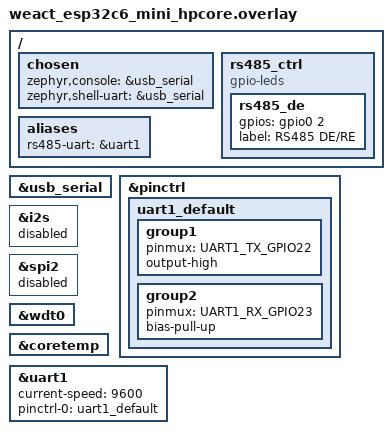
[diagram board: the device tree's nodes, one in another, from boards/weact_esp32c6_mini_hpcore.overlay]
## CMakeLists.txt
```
cmake_minimum_required(VERSION 3.20.0)
find_package(Zephyr REQUIRED HINTS $ENV{ZEPHYR_BASE})

project(ami-lwm2m-client
    VERSION 0.6.43
    DESCRIPTION "AMI Node: LwM2M client over Thread (ESP32-C6)"
    LANGUAGES C
)

# Source files
target_sources(app PRIVATE
    src/main.c
    src/lwm2m_discover.c
    src/lwm2m_watchdog.c
    src/hw_watchdog.c
    src/rgb_led.c
    src/lwm2m_obj_power_meter.c
    src/firmware_update.c
    src/thread_conn_monitor.c
    src/lwm2m_obj_thread_net.c
    src/lwm2m_obj_thread_neighbor.c
    src/lwm2m_obj_thread_commission.c
    src/lwm2m_obj_thread_cli.c
    src/rs485_uart.c
    src/dlms_hdlc.c
    src/dlms_cosem.c
    src/dlms_meter.c
    src/post_mortem.c
    src/lwm2m_obj_light_control.c
    src/lwm2m_obj_thread_role.c
    src/coap_keepalive.c
    src/coap_diag.c
)

# Include path for custom LwM2M object internal headers
target_include_directories(app PRIVATE
    ${ZEPHYR_BASE}/subsys/net/lib/lwm2m
)

# CoAP diag server (src/coap_diag.c): COAP_SERVICE_DEFINE(diag_service, ...)
# places its resources into a per-service iterable section
# "coap_resource_diag_service". Register that section on BOTH linker paths so
# the _coap_resource_diag_service_list_start/end symbols resolve. See
# sections-ram.ld and samples/net/sockets/coap_server for the upstream pattern.
zephyr_linker_sources(DATA_SECTIONS sections-ram.ld)
zephyr_iterable_section(
    NAME coap_resource_diag_service
    GROUP DATA_REGION ${XIP_ALIGN_WITH_INPUT})
```

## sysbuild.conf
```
# Sysbuild configuration — only consumed when building with `west build --sysbuild`.
#
# v0.6.27 OTA: enable the MCUboot bootloader image. sysbuild builds two
# images: the MCUboot 2nd-stage bootloader (flashed at 0x0 / boot_partition)
# and this app, signed + headered, linked to run from slot0_partition
# (0x20000). MCUboot validates the signature/header at boot and chain-loads
# slot0, or swaps in a pending image from slot1 after an OTA.
#
# The legacy non-sysbuild build (tools/build_firmware.py) is unaffected: it
# never passes --sysbuild, so this file is ignored and the monolithic
# image-at-0x0 build still works for nodes not yet migrated to MCUboot.
SB_CONFIG_BOOTLOADER_MCUBOOT=y
```

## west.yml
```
# West manifest for the AMI LwM2M Node firmware (freestanding Zephyr application).
#
# This pins the EXACT Zephyr revision the firmware was built + validated on:
#   Zephyr 4.3.99 dev snapshot  (v4.3.0-6612-g6159cb3fecf)
#   Zephyr SDK 0.17.0 · west 1.5.0 · esptool 5.2.0 · board xiao_esp32c6/esp32c6/hpcore
#
# Reproduce the workspace on a fresh machine:
#   mkdir ami-ws && cd ami-ws
#   git clone https://github.com/jsebgiraldo/ami-lwm2m-node.git
#   west init -l ami-lwm2m-node
#   west update            # pulls Zephyr + modules at the pinned revision (large)
#   west zephyr-export
#   pip install -r ami-lwm2m-node/requirements.txt
#   pip install -r zephyr/scripts/requirements.txt
# Then apply the out-of-tree hook (tools/ZEPHYR_PATCHES.md) and build
# (python ami-lwm2m-node/tools/build_prod.py). See README.md.
manifest:
  version: "1.0"
  remotes:
    - name: zephyrproject-rtos
      url-base: https://github.com/zephyrproject-rtos
  projects:
    - name: zephyr
      remote: zephyrproject-rtos
      revision: 6159cb3fecf85090c8d552d5dfa4d97f4cb1231e
      # import: true pulls Zephyr's full module set at this revision — heavier
      # but guarantees a complete, build-able tree (no missing-module surprises).
      # To trim for ESP32-C6 only, replace with an import: { name-allowlist: [...] }.
      import: true
  self:
    path: ami-lwm2m-node
```

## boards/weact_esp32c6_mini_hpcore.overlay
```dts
/*
 * Devicetree overlay for WeAct ESP32-C6 Mini / ESP32-C6 SuperMini
 * (drop-in replacement for the Seeed XIAO ESP32-C6 in this fleet)
 *
 * Differences vs xiao_esp32c6_hpcore.overlay:
 *   - Console stays on the board-default UART0 (GPIO16/17), NOT usb_serial
 *     — that's how the WeAct board.dts wires its USB-C through.
 *   - SPI2 default pinmux on the WeAct DTS uses GPIO2 for SCLK, which
 *     collides with our RS485 DE/RE on GPIO2. We disable spi2 to keep
 *     GPIO2 free.
 *   - Single onboard LED on GPIO8 (WeAct uses it as WS2812 RGB via I2S
 *     in its DTS; we disable that and drive it via the existing
 *     direct-register WS2812 bit-bang in src/rgb_led.c which already
 *     targets GPIO8 — see header note in that file).
 *
 * DLMS RS485 wiring (same as XIAO):
 *   UART1 TX = GPIO22  (D4 equivalent on XIAO)
 *   UART1 RX = GPIO23
 *   DE/RE    = GPIO2   (HIGH = TX)
 */

#include <zephyr/dt-bindings/pinctrl/esp-pinctrl-common.h>
#include <zephyr/dt-bindings/pinctrl/esp32c6-pinctrl.h>
#include <zephyr/dt-bindings/pinctrl/esp32c6-gpio-sigmap.h>

/* The WeAct board DTS routes the console to UART0 (GPIO16/17) — that
 * matches their boards which solder a CH340/CP2102 between USB-C and
 * UART0. The ESP32-C6 SuperMini wires USB-C straight to the chip's
 * native USB-Serial-JTAG (GPIO12/13), so we override the chosen console
 * to usb_serial; that way `west monitor` / pyserial on the COM port the
 * board enumerates as actually sees the firmware logs.
 */
/ {
	chosen {
		zephyr,console = &usb_serial;
		zephyr,shell-uart = &usb_serial;
	};
};

&usb_serial {
	status = "okay";
};

&pinctrl {
	uart1_default: uart1_default {
		group1 {
			pinmux = <UART1_TX_GPIO22>;
			output-high;
		};
		group2 {
			pinmux = <UART1_RX_GPIO23>;
			bias-pull-up;
		};
	};
};

/* Disable WeAct's I2S-driven WS2812 — we drive GPIO8 directly from
 * src/rgb_led.c (bit-bang, same as on XIAO). */
&i2s {
	status = "disabled";
};

/* Disable SPI2 — its default SCLK pin collides with our RS485 DE/RE (GPIO2). */
&spi2 {
	status = "disabled";
};

/* WeAct's I2C0 lives on GPIO14/15 which don't collide with anything we
 * need — leave it on for now (the application doesn't use it). */

/* HW watchdog backstop (same role as on XIAO). */
&wdt0 {
	status = "okay";
};

/* On-die temperature sensor. */
&coretemp {
	status = "okay";
};

/* DLMS RS485 UART. */
&uart1 {
	status = "okay";
	current-speed = <9600>;
	pinctrl-0 = <&uart1_default>;
	pinctrl-names = "default";
};

/* RS485 DE/RE control as a plain GPIO + a led0 alias the rgb_led driver
 * doesn't need but other code (and Zephyr conventions) expect. */
/ {
	rs485_ctrl: rs485_ctrl {
		compatible = "gpio-leds";  /* reuse for a single GPIO node */
		rs485_de: rs485_de {
			gpios = <&gpio0 2 GPIO_ACTIVE_HIGH>;
			label = "RS485 DE/RE";
		};
	};

	aliases {
		rs485-uart = &uart1;
	};
};
```

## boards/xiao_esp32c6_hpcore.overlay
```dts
/*
 * Devicetree overlay for XIAO ESP32-C6 + Seeed RS485 Expansion Board
 *
 * Seeed RS485 Expansion Board wiring (per Seeed wiki & TP8485E transceiver):
 *   D4 (GPIO22) = TX  (MCU → transceiver DI → RS485 bus)
 *   D5 (GPIO23) = RX  (RS485 bus → transceiver RO → MCU)
 *   D2 (GPIO2)  = DE/RE  (HIGH = transmit, LOW = receive)
 *
 * We configure UART1 on GPIO22(TX)/GPIO23(RX) for DLMS/COSEM serial
 * communication with the Microstar smart meter.
 *
 * Note: GPIO22/GPIO23 are shared with I2C0 — I2C is disabled here.
 */

#include <zephyr/dt-bindings/pinctrl/esp-pinctrl-common.h>
#include <zephyr/dt-bindings/pinctrl/esp32c6-pinctrl.h>
#include <zephyr/dt-bindings/pinctrl/esp32c6-gpio-sigmap.h>
#include <zephyr/dt-bindings/led/led.h>

/* Add UART1 pin configuration */
&pinctrl {
	uart1_default: uart1_default {
		group1 {
			pinmux = <UART1_TX_GPIO22>;
			output-high;
		};

		group2 {
			pinmux = <UART1_RX_GPIO23>;
			bias-pull-up;
		};
	};

	/* v0.6.54: SPI2 binding REVERTED -- enabling SPI was breaking the
	 * 802.15.4 radio attach. WS2812 reverts to custom bit-bang in rgb_led.c. */
};

/* Disable I2C0 since GPIO22/23 are now used for UART1 (RS485) */
&i2c0 {
	status = "disabled";
};

/* Enable Timer-Group 0 hardware watchdog (v0.6.13+, PRIO 9).
 * Last-resort defense against firmware hangs that the soft watchdog
 * cannot recover from (system_workq stuck, scheduler stalled, USB
 * drain blocked at sys_reboot). Driven via Zephyr's task_wdt subsystem
 * — see src/hw_watchdog.c. */
&wdt0 {
	status = "okay";
};

/* Enable on-die temperature sensor (v0.6.11+).
 * Used to monitor SoC self-heating during operation. Read via
 * sensor_sample_fetch + sensor_channel_get(SENSOR_CHAN_DIE_TEMP).
 * Range: -40°C to +125°C. Accuracy ~±2°C after factory calibration. */
&coretemp {
	status = "okay";
};

/* v0.6.34 dropped CPU to 80 MHz to cut self-heating; v0.6.36 REVERTED to
 * 160 MHz (no override here — falls back to the SoC default in
 * esp32c6_common.dtsi). Reason: 80 MHz roughly halves blockwise CoAP/MCUboot
 * throughput, pushing single-node OTA from ~10 min (160) to >50 min (80) —
 * past the Edge's LWM2M_TIMEOUT=600000 (10 min), so transfers loop in state=1
 * Downloading and never reach Downloaded. Measured A/B: d2b4 @ 160MHz reached
 * Downloaded in 10.3 min; c61c @ 80MHz never finished in 50+ min over two
 * attempts. The thermal gain was only ~2C avg (radio rx-on dominates heat),
 * not worth losing fleet OTA. Keeping DLMS_POLL=60s + NOTIFY=60s for the mesh
 * load reduction (those don't affect CPU throughput). */

/* Enable UART1 for RS485 DLMS communication */
&uart1 {
	status = "okay";
	current-speed = <9600>;
	pinctrl-0 = <&uart1_default>;
	pinctrl-names = "default";
};

/* RS485 DE/RE control pin — defined as a GPIO node */
/ {
	rs485_ctrl: rs485_ctrl {
		compatible = "gpio-leds";  /* Reuse gpio-leds compatible for simple GPIO */
		rs485_de: rs485_de {
			gpios = <&gpio0 2 GPIO_ACTIVE_HIGH>;
			label = "RS485 DE/RE";
		};
	};

	aliases {
		rs485-uart = &uart1;
	};

};

/* v0.6.54: WS2812 SPI binding REVERTED -- v0.6.53 enabling CONFIG_SPI=y broke
 * the 802.15.4 radio attach across all 30 nodes (1h soak collapsed mesh from
 * 15 active to 0). LED driver returns to custom bit-bang in src/rgb_led.c. */
```

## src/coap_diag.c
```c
/*
 * Object 33001 gives the server LwM2M-mediated role control; this gives the
 * server a *direct* IPv6 read path. A minimal CoAP GET server on port 5685
 * exposing two resources, both independent of the LwM2M registration:
 *
 *   coap://[<node-ipv6>]:5685/diag  -> node status snapshot (JSON)
 *      {"fw":"0.7.15-diag","role":"Router","uptime_s":1234,"resets":7,
 *       "reg_ok":3,"recover":5,"wdog":0,"boot_burst":0,
 *       "partition":123456,"rloc16":"0x4c00"}
 *
 *   coap://[<node-ipv6>]:5685/ami   -> live AMI metering / active OBIS (JSON)
 *      {"valid":true,"vr":122.24,...,"ptot":0.03,"eact":61100.0,"freq":59.94,
 *       "reads":15,"errs":0,"mask":"0x0007ffff","age_s":3}
 *
 * Useful precisely for the "inactive on TB" nodes: if a node is still on the
 * Thread mesh it answers these GETs even when its LwM2M session is down, so the
 * server can tell "reachable but not registered" from "off the mesh" AND pull
 * the instantaneous meter reading without waiting on the LwM2M Observe cadence.
 */
#include <zephyr/kernel.h>
#include <zephyr/logging/log.h>
#include <zephyr/net/socket.h>
#include <zephyr/net/coap.h>
#include <zephyr/net/coap_service.h>
#include <zephyr/net/openthread.h>
#include <openthread/instance.h>
#include <openthread/thread.h>
#include <stdio.h>
#include <string.h>

#include "coap_diag.h"
#include "dlms_meter.h"

LOG_MODULE_REGISTER(coap_diag, LOG_LEVEL_INF);

/* Diagnostic counter getters (defined in main.c). */
extern uint32_t lwm2m_diag_get_total_resets(void);
extern uint32_t lwm2m_diag_get_reg_success(void);
extern uint32_t lwm2m_diag_get_recover_count(void);
extern uint32_t lwm2m_diag_get_watchdog_count(void);
extern uint32_t lwm2m_diag_get_boot_burst(void);

/* Current meter readings snapshot (main.c). Reads last_readings, which is
 * populated in BOTH demo and real modes — see ami_get_last_readings(). */
extern bool ami_get_last_readings(struct meter_readings *out);

static const char *g_fw = "?";

/* CoAP diag server: distinct port so it never collides with the LwM2M client's
 * sockets. Auto-starts once the network interface is up. */
static uint16_t coap_diag_port = 5685;
COAP_SERVICE_DEFINE(diag_service, "::", &coap_diag_port, COAP_SERVICE_AUTOSTART);

/* Payload budget: leave headroom under the server message size for the CoAP
 * header + token + Content-Format option (~16 bytes) so append_payload never
 * overflows the response buffer. */
#define DIAG_JSON_MAX  (CONFIG_COAP_SERVER_MESSAGE_SIZE - 64)

static const char *role_str(otDeviceRole r)
{
	switch (r) {
	case OT_DEVICE_ROLE_DISABLED: return "Disabled";
	case OT_DEVICE_ROLE_DETACHED: return "Detached";
	case OT_DEVICE_ROLE_CHILD:    return "Child";
	case OT_DEVICE_ROLE_ROUTER:   return "Router";
	case OT_DEVICE_ROLE_LEADER:   return "Leader";
	default:                      return "?";
	}
}

/* Build + send a 2.05 Content response carrying `json` (len bytes) as
 * application/json, echoing the request token/mid and ACK-ing CON requests. */
static int diag_send_json(struct coap_resource *resource, struct coap_packet *request,
			  struct sockaddr *addr, socklen_t addr_len,
			  const char *json, int len)
{
	uint8_t data[CONFIG_COAP_SERVER_MESSAGE_SIZE];
	struct coap_packet response;
	uint8_t token[COAP_TOKEN_MAX_LEN];
	uint16_t id = coap_header_get_id(request);
	uint8_t tkl = coap_header_get_token(request, token);
	uint8_t type = (coap_header_get_type(request) == COAP_TYPE_CON)
		       ? COAP_TYPE_ACK : COAP_TYPE_NON_CON;

	int r = coap_packet_init(&response, data, sizeof(data), COAP_VERSION_1, type,
				 tkl, token, COAP_RESPONSE_CODE_CONTENT, id);
	if (r < 0) {
		return r;
	}
	r = coap_append_option_int(&response, COAP_OPTION_CONTENT_FORMAT,
				   COAP_CONTENT_FORMAT_APP_JSON);
	if (r < 0) {
		return r;
	}
	r = coap_packet_append_payload_marker(&response);
	if (r < 0) {
		return r;
	}
	r = coap_packet_append_payload(&response, json, len);
	if (r < 0) {
		return r;
	}
	return coap_resource_send(resource, &response, addr, addr_len, NULL);
}

static int diag_get(struct coap_resource *resource, struct coap_packet *request,
		    struct sockaddr *addr, socklen_t addr_len)
{
	otInstance *ot = openthread_get_default_instance();
	otDeviceRole role = ot ? otThreadGetDeviceRole(ot) : OT_DEVICE_ROLE_DISABLED;
	uint32_t partition = ot ? otThreadGetPartitionId(ot) : 0;
	uint16_t rloc16 = ot ? otThreadGetRloc16(ot) : 0;
	uint32_t up = (uint32_t)(k_uptime_get() / 1000);

	char json[DIAG_JSON_MAX];
	int len = snprintf(json, sizeof(json),
		"{\"fw\":\"%s\",\"role\":\"%s\",\"uptime_s\":%u,\"resets\":%u,"
		"\"reg_ok\":%u,\"recover\":%u,\"wdog\":%u,\"boot_burst\":%u,"
		"\"partition\":%u,\"rloc16\":\"0x%04x\"}",
		g_fw, role_str(role), up,
		lwm2m_diag_get_total_resets(), lwm2m_diag_get_reg_success(),
		lwm2m_diag_get_recover_count(), lwm2m_diag_get_watchdog_count(),
		lwm2m_diag_get_boot_burst(), partition, rloc16);
	if (len < 0 || len >= (int)sizeof(json)) {
		len = (int)sizeof(json) - 1;
	}
	return diag_send_json(resource, request, addr, addr_len, json, len);
}

static int ami_get(struct coap_resource *resource, struct coap_packet *request,
		   struct sockaddr *addr, socklen_t addr_len)
{
	struct meter_readings m;
	bool have = ami_get_last_readings(&m);

	char json[DIAG_JSON_MAX];
	int len;
	if (!have) {
		/* No successful DLMS read yet (no meter attached, or bus down). */
		len = snprintf(json, sizeof(json), "{\"valid\":false}");
	} else {
		int64_t age_s = (k_uptime_get() - m.timestamp_ms) / 1000;
		len = snprintf(json, sizeof(json),
			"{\"valid\":true,"
			"\"vr\":%.2f,\"vs\":%.2f,\"vt\":%.2f,"
			"\"ir\":%.3f,\"is\":%.3f,\"it\":%.3f,"
			"\"pr\":%.3f,\"ps\":%.3f,\"pt\":%.3f,"
			"\"ptot\":%.3f,\"qtot\":%.3f,\"stot\":%.3f,\"pf\":%.3f,"
			"\"eact\":%.3f,\"ereact\":%.3f,\"eapp\":%.3f,"
			"\"freq\":%.2f,"
			"\"reads\":%d,\"errs\":%d,\"mask\":\"0x%08x\",\"age_s\":%lld}",
			m.voltage_r, m.voltage_s, m.voltage_t,
			m.current_r, m.current_s, m.current_t,
			m.active_power_r, m.active_power_s, m.active_power_t,
			m.total_active_power, m.total_reactive_power,
			m.total_apparent_power, m.total_power_factor,
			m.active_energy, m.reactive_energy, m.apparent_energy,
			m.frequency,
			m.read_count, m.error_count, m.field_mask,
			(long long)age_s);
	}
	if (len < 0 || len >= (int)sizeof(json)) {
		len = (int)sizeof(json) - 1;
	}
	return diag_send_json(resource, request, addr, addr_len, json, len);
}

static const char * const diag_path[] = { "diag", NULL };
COAP_RESOURCE_DEFINE(diag_resource, diag_service, {
	.get = diag_get,
	.path = diag_path,
});

static const char * const ami_path[] = { "ami", NULL };
COAP_RESOURCE_DEFINE(ami_resource, diag_service, {
	.get = ami_get,
	.path = ami_path,
});

int coap_diag_init(const char *fw_version)
{
	if (fw_version) {
		g_fw = fw_version;
	}
	LOG_INF("CoAP diag GET server up on [::]:%u  /diag (node) + /ami (meter)",
		coap_diag_port);
	return 0;
}
```

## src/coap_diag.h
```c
#ifndef COAP_DIAG_H
#define COAP_DIAG_H

/* Object-independent, on-demand IPv6 diagnostics.
 *
 * Starts a tiny CoAP server (Zephyr coap_service) that answers a GET to
 *   coap://[<node-ipv6>]:5685/diag
 * with a JSON snapshot of the node's live state (role, uptime, resets,
 * registration counters, partition, rloc16). Works over the node's Thread
 * IPv6 address and is INDEPENDENT of LwM2M/CoAP-observe — so the server can
 * query a node directly even when it is not registered on TB.
 *
 * Call once after OpenThread is initialised; the service auto-starts when the
 * network comes up. Pass the firmware version string so it is reported.
 */
int coap_diag_init(const char *fw_version);

#endif /* COAP_DIAG_H */
```

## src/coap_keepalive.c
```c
/*
 * CoAP-level keepalive — see header for design notes.
 *
 * Why notify on TD_UPTIME_S_RID rather than introduce a new resource:
 *   - It's already declared observable on TB Edge (we depend on this
 *     for liveness in tools/tb_edge_monitoring_setup.py OBSERVE_ADDITIONS).
 *   - conn_monitor already updates it every ~60s, so the value is
 *     non-stale; we just bump the notify cadence floor to 300s without
 *     duplicating state.
 *   - Engine pmin/pmax write-attributes on /33000/0/10 (typical pmin=30,
 *     pmax=300 from TB Edge) won't suppress us — we fire exactly at pmax.
 *
 * Boot grace: wait 60s before the first keepalive so the LwM2M engine
 * has time to complete REGISTER. If we fire before REGISTER ACK, the
 * notify is silently dropped (no observer to notify against), which is
 * fine but pollutes early-boot logs.
 */

#include "coap_keepalive.h"

#include <zephyr/kernel.h>
#include <zephyr/logging/log.h>
#include <zephyr/net/lwm2m.h>
#include <zephyr/sys/atomic.h>

#include "lwm2m_obj_thread_diag.h"
#include "lwm2m_watchdog.h"
#include "hw_watchdog.h"

LOG_MODULE_REGISTER(coap_keepalive, LOG_LEVEL_INF);

#define KEEPALIVE_PERIOD_S    CONFIG_AMI_COAP_KEEPALIVE_PERIOD_S
#define KEEPALIVE_BOOT_GRACE_S 60
/* v0.6.69: was 1024 — code-review audit caught the same pattern that
 * bit lwm2m_wdog in v0.6.63: LOG_WRN/LOG_ERR with %s/%u args triggers
 * cbprintf_package_convert recursion needing ~3 KB headroom. First fail
 * burst (~270 s after socket dies) overflowed the 1024-byte stack and
 * silently killed the keepalive thread → board sat as zombie because
 * no further notifies attempted → silence watchdog never saw heartbeat
 * absence. This was a candidate root cause of the 8/30 stuck boards in
 * v0.6.67's 2h soak. 4096 mirrors lwm2m_wdog headroom. */
#define KEEPALIVE_STACK_SZ    4096
/* Preemptive prio — not coop — so it cannot starve LwM2M engine threads.
 * Priority chosen well below lwm2m_wdog (PREEMPT 7) so the silence
 * watchdog still has precedence if it ever decides to act. */
#define KEEPALIVE_PRIO        K_PRIO_PREEMPT(9)

/* v0.6.68: when notify_observer() fails N times in a row, the engine is
 * almost certainly in a stuck state (ECANCELED, socket dead, etc.). Fire
 * recover_work directly instead of waiting for the silence watchdog.
 * N=3 chosen to match the engine's internal CoAP CON retransmit budget. */
#define KEEPALIVE_FAIL_THRESHOLD 3

/* Diag — increment on every keepalive emit so the operator can verify
 * via Object 33000 that the worker is actually running. */
static atomic_t keepalive_emit_count = ATOMIC_INIT(0);
/* v0.6.68: consecutive failed notify_observer() returns. Reset on success. */
static atomic_t keepalive_consec_fail = ATOMIC_INIT(0);

/* Hook into main.c's recover_work — same path the silence watchdog uses. */
extern struct k_work_delayable lwm2m_recover_work;
extern void lwm2m_diag_record_error(int err);

uint32_t coap_keepalive_get_emit_count(void)
{
	return (uint32_t)atomic_get(&keepalive_emit_count);
}

uint32_t coap_keepalive_get_consec_fail(void)
{
	return (uint32_t)atomic_get(&keepalive_consec_fail);
}

static void keepalive_thread_fn(void *p1, void *p2, void *p3)
{
	ARG_UNUSED(p1); ARG_UNUSED(p2); ARG_UNUSED(p3);

	LOG_INF("CoAP keepalive thread up: period=%us, grace=%us, "
		"target=/33000/0/%u (uptime_s)",
		KEEPALIVE_PERIOD_S, KEEPALIVE_BOOT_GRACE_S,
		TD_UPTIME_S_RID);

	/* Don't fight the boot REGISTER. */
	k_sleep(K_SECONDS(KEEPALIVE_BOOT_GRACE_S));

	for (;;) {
		/* Notify the engine that /33000/0/uptime_s "changed" — engine
		 * will queue a CoAP CON message. If the socket is dead the
		 * engine's notify_message_timeout_cb() fires after 3 retries
		 * and calls lwm2m_rd_client_timeout(), which kicks the state
		 * machine back to ENGINE_DO_REGISTRATION. Our recover_work in
		 * main.c rides the same state machine.
		 */
		int ret = lwm2m_notify_observer(THREAD_DIAG_OBJECT_ID, 0,
						TD_UPTIME_S_RID);
		atomic_inc(&keepalive_emit_count);

		if (ret >= 0) {
			/* v0.6.75: ret is the COUNT of observers notified, NOT a
			 * 0=OK status. lwm2m_notify_observer_path() returns the
			 * number of matching observers (0 = none) or <0 on a real
			 * engine error. The v0.6.68 code tested `ret == 0` as
			 * "queued OK", which INVERTED the logic: a board that IS
			 * being observed on /33000/0/uptime_s returns ret>0 and was
			 * mis-counted as a failure → 3 strikes → forced recover →
			 * COLD reboot every ~12 min (3 × keepalive_period after the
			 * 60 s boot grace). Boards with NO observer (ret==0, e.g.
			 * minimal builds without Object 33000) were the only ones
			 * that survived — the perverse opposite of what we want.
			 * Forensic proof: 1494 (Object 33000 + observed) looped at
			 * uptime≈706 s / reg_age≈660 s with heap 100 % free; f7b4/
			 * fbb8 (minimal, ret==0) stayed up. ret>=0 means the engine
			 * processed the notify (alive) — feed the watchdog. */
			lwm2m_watchdog_emit_event();
			atomic_set(&keepalive_consec_fail, 0);
			/* v0.7.9: ret>0 = REAL observers were notified, so telemetry
			 * is actually being delivered (not just queued). Feed the
			 * inbound delivery-liveness gate. ret==0 = registered but
			 * NOBODY is observing us — the stuck-session signature — so we
			 * deliberately do NOT feed it: after
			 * CONFIG_AMI_DELIVERY_LIVENESS_TIMEOUT_S the HW feeder cold-
			 * resets, forcing a fresh REGISTER that re-establishes observes.
			 * The note_delivery() latch (ever_had_observer) means a build
			 * that is never observed never arms this gate. */
			if (ret > 0) {
				hw_watchdog_note_delivery();
			}
			LOG_DBG("keepalive: notify ok, %d observer(s) (cnt=%u)",
				ret, (uint32_t)atomic_get(&keepalive_emit_count));
		} else {
			/* v0.6.68: real engine error (ret < 0, e.g. -ENOMEM /
			 * socket dead). Count consecutive fails; after
			 * KEEPALIVE_FAIL_THRESHOLD, kick recover directly. This
			 * catches stuck states the silence watchdog cannot see fast
			 * enough (engine internally cancelled / socket dead). */
			int fails = (int)atomic_inc(&keepalive_consec_fail) + 1;
			LOG_WRN("keepalive: notify failed ret=%d "
				"(consec=%d/%d, cnt=%u)",
				ret, fails, KEEPALIVE_FAIL_THRESHOLD,
				(uint32_t)atomic_get(&keepalive_emit_count));
			if (fails >= KEEPALIVE_FAIL_THRESHOLD) {
				LOG_ERR("keepalive: %d consecutive failures — "
					"forcing recover_work", fails);
				lwm2m_diag_record_error(ret);
				atomic_set(&keepalive_consec_fail, 0);
				k_work_reschedule(&lwm2m_recover_work,
						  K_NO_WAIT);
			}
		}

		k_sleep(K_SECONDS(KEEPALIVE_PERIOD_S));
	}
}

K_THREAD_STACK_DEFINE(keepalive_stack, KEEPALIVE_STACK_SZ);
static struct k_thread keepalive_thread_data;

void coap_keepalive_init(void)
{
	k_thread_create(&keepalive_thread_data,
			keepalive_stack,
			K_THREAD_STACK_SIZEOF(keepalive_stack),
			keepalive_thread_fn,
			NULL, NULL, NULL,
			KEEPALIVE_PRIO,
			0,
			K_NO_WAIT);
	k_thread_name_set(&keepalive_thread_data, "coap_keepalive");
}
```

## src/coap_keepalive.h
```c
/*
 * CoAP-level keepalive (v0.6.67)
 *
 * Periodic notify on an existing observed resource so the engine emits a
 * confirmable CoAP message every N seconds, independent of REG_UPDATE
 * cadence and resource value changes. When the server socket dies (TB Edge
 * restart, mesh disruption, OTBR reboot), Zephyr's LwM2M engine detects
 * the CON timeout after 3 retries, fires lwm2m_rd_client_timeout(), and
 * forces a fresh REGISTER through the normal recover path. Without this,
 * a long client lifetime (e.g. 86400s, set to work around TB Edge's
 * REG_UPDATE/active tracking bug) means dead sockets aren't detected for
 * up to 2 days — the silence watchdog only fires at 2 * lifetime.
 */
#ifndef AMI_COAP_KEEPALIVE_H_
#define AMI_COAP_KEEPALIVE_H_

/* Start the keepalive thread. Call once after lwm2m engine init. */
void coap_keepalive_init(void);

/* Diag accessors (v0.6.68). */
#include <stdint.h>
uint32_t coap_keepalive_get_emit_count(void);
uint32_t coap_keepalive_get_consec_fail(void);

#endif /* AMI_COAP_KEEPALIVE_H_ */
```

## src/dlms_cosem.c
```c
/*
 * DLMS/COSEM Application Layer
 *
 * Implements COSEM AARQ, GET.request, and response decoding.
 * Targeting DLMS Logical Name (LN) referencing with LLS authentication.
 */

#include <zephyr/kernel.h>
#include <zephyr/logging/log.h>
#include <string.h>
#include <math.h>

#include "dlms_cosem.h"

LOG_MODULE_REGISTER(dlms_cosem, LOG_LEVEL_DBG);

/*
 * Application Context Name for LN referencing (no ciphering):
 *   joint-iso-itu-t(2) country(16) country-name(756 = CH)
 *   identified-organization(5) DLMS-UA(8) application-context(1)
 *   context-id-LN(1) = 2.16.756.5.8.1.1
 * BER encoding: 60 36 A1 09 06 07 60 85 74 05 08 01 01
 */
static const uint8_t app_context_ln[] = {
	0x60, 0x85, 0x74, 0x05, 0x08, 0x01, 0x01
};

int cosem_build_aarq(uint8_t *buf, size_t buf_size,
		     const uint8_t *password, size_t pass_len)
{
	if (!buf || buf_size < 64) {
		return -EINVAL;
	}

	uint8_t *p = buf;
	uint8_t *len_pos;

	/* AARQ tag */
	*p++ = COSEM_TAG_AARQ;
	len_pos = p++;  /* Length placeholder */

	/*
	 * Application Context Name [1]
	 *   A1 09
	 *     06 07 60 85 74 05 08 01 01
	 */
	*p++ = 0xA1;  /* Context tag [1] */
	*p++ = 0x09;
	*p++ = 0x06;  /* OID type */
	*p++ = 0x07;  /* OID length */
	memcpy(p, app_context_ln, sizeof(app_context_ln));
	p += sizeof(app_context_ln);

	/*
	 * Sender ACSE Requirements [8A] (if password authentication)
	 *   8A 02 07 80  — bit string, authentication functional unit
	 */
	if (password && pass_len > 0) {
		*p++ = 0x8A;  /* Context tag [10] implicit */
		*p++ = 0x02;
		*p++ = 0x07;  /* Unused bits = 7 → only bit 0 used */
		*p++ = 0x80;  /* Authentication functional unit */

		/*
		 * Mechanism Name [8B]
		 *   8B 07 60 85 74 05 08 02 01
		 *   = 2.16.756.5.8.2.1 (Low Level Security)
		 */
		*p++ = 0x8B;  /* Context tag [11] implicit */
		*p++ = 0x07;
		*p++ = 0x60;
		*p++ = 0x85;
		*p++ = 0x74;
		*p++ = 0x05;
		*p++ = 0x08;
		*p++ = 0x02;
		*p++ = 0x01;  /* LLS mechanism */

		/*
		 * Calling Authentication Value [AC]
		 *   AC <len>
		 *     80 <pass_len> <password>
		 */
		*p++ = 0xAC;  /* Context tag [12] constructed */
		*p++ = (uint8_t)(pass_len + 2);
		*p++ = 0x80;  /* charstring tag (context-specific) */
		*p++ = (uint8_t)pass_len;
		memcpy(p, password, pass_len);
		p += pass_len;
	}

	/*
	 * User Information [BE]
	 *   BE <len>
	 *     04 <len>  (OCTET STRING — xDLMS InitiateRequest)
	 *       01 00 00 00  — proposed DLMS version, etc.
	 *       06 5F 1F     — proposed conformance (bits)
	 *       04 00        — proposed QoS
	 *       00 07        — proposed-dlms-version-number = 6
	 *       00 80        — max-receive-pdu-size = 128
	 *
	 * InitiateRequest:
	 *   01     — xDLMS InitiateRequest tag
	 *   00     — dedicated-key absent
	 *   00     — response-allowed = TRUE (default)
	 *   00     — proposed-quality-of-service = 0
	 *   06     — proposed-dlms-version-number = 6
	 *   5F 1F 04 00 00 1E 1D 00 80
	 *          — proposed conformance block (3 bytes tag + 4 bytes)
	 *   00 80  — client-max-receive-pdu-size = 128
	 */
	static const uint8_t initiate_request[] = {
		0x01,                   /* xDLMS InitiateRequest */
		0x00,                   /* dedicated-key absent */
		0x00,                   /* response-allowed = TRUE */
		0x00,                   /* proposed-quality-of-service */
		0x06,                   /* proposed-dlms-version-number = 6 */
		0x5F, 0x1F,             /* Conformance tag */
		0x04,                   /* Conformance length = 4 */
		0x00,                   /* Unused bits */
		/* Conformance block (24 bits):
		 * bit 0: general-protection
		 * bit 3: read, bit 4: write
		 * bit 8: unconfirmed-write
		 * bit 9: attribute0-supported-with-get
		 * bit 12: get, bit 15: set
		 * bit 19: selective-access, bit 20: event-notification
		 * bit 23: action
		 * We request: get(12) + selective-access(19) + block-transfer-with-get(14)
		 * = 0x00 1C 03 = get + set + selective_access + block_transfer
		 */
		0x00, 0x18, 0x1D,
		0x00, 0x80,             /* client-max-receive-pdu-size = 128 */
	};

	*p++ = 0xBE;  /* Context tag [14] constructed */
	*p++ = (uint8_t)(sizeof(initiate_request) + 2);
	*p++ = 0x04;  /* OCTET STRING tag */
	*p++ = (uint8_t)sizeof(initiate_request);
	memcpy(p, initiate_request, sizeof(initiate_request));
	p += sizeof(initiate_request);

	/* Fill in overall AARQ length */
	*len_pos = (uint8_t)(p - len_pos - 1);

	size_t total = p - buf;
	LOG_DBG("AARQ built: %u bytes", (unsigned)total);
	return (int)total;
}

int cosem_parse_aare(const uint8_t *data, size_t len)
{
	if (!data || len < 3) {
		return -EINVAL;
	}

	if (data[0] != COSEM_TAG_AARE) {
		LOG_ERR("AARE: Wrong tag: 0x%02X (expected 0x61)", data[0]);
		return -EPROTO;
	}

	/*
	 * Scan for Association Result [A2]:
	 *   A2 03 02 01 <result>
	 * result: 0 = accepted, 1 = rejected-permanent, 2 = rejected-transient
	 */
	for (size_t i = 2; i < len - 4; i++) {
		if (data[i] == 0xA2 && data[i + 1] == 0x03 &&
		    data[i + 2] == 0x02 && data[i + 3] == 0x01) {
			uint8_t result = data[i + 4];
			if (result == 0) {
				LOG_INF("AARE: Association ACCEPTED");
				return 0;
			}
			LOG_ERR("AARE: Association REJECTED (result=%u)", result);
			return -EACCES;
		}
	}

	LOG_WRN("AARE: Could not find association-result");
	return -EPROTO;
}

int cosem_build_get_request(uint8_t *buf, size_t buf_size,
			    uint8_t invoke_id,
			    const struct cosem_attr_desc *attr)
{
	if (!buf || !attr || buf_size < 16) {
		return -EINVAL;
	}

	uint8_t *p = buf;

	/* GET.request tag */
	*p++ = COSEM_TAG_GET_REQUEST;
	/* GET.request-normal */
	*p++ = GET_REQUEST_NORMAL;
	/* Invoke ID and priority */
	*p++ = invoke_id;

	/* COSEM attribute descriptor */
	/* Class ID (2 bytes) */
	*p++ = (attr->class_id >> 8) & 0xFF;
	*p++ = attr->class_id & 0xFF;

	/* OBIS code (6 bytes) */
	*p++ = attr->obis.a;
	*p++ = attr->obis.b;
	*p++ = attr->obis.c;
	*p++ = attr->obis.d;
	*p++ = attr->obis.e;
	*p++ = attr->obis.f;

	/* Attribute ID */
	*p++ = attr->attribute_id;

	/* Access selection = 0 (no selective access) */
	*p++ = 0x00;

	size_t total = p - buf;
	LOG_DBG("GET.request built: %u bytes, class=%u, OBIS=%u-%u:%u.%u.%u*%u, attr=%d",
		(unsigned)total, attr->class_id,
		attr->obis.a, attr->obis.b, attr->obis.c,
		attr->obis.d, attr->obis.e, attr->obis.f,
		attr->attribute_id);

	return (int)total;
}

int cosem_decode_data(const uint8_t *data, size_t len,
		      struct cosem_get_result *result)
{
	if (!data || !result || len < 1) {
		return -EINVAL;
	}

	result->data_type = data[0];
	size_t consumed = 1;

	switch (data[0]) {
	case COSEM_TYPE_NULL_DATA:
		result->value.u64 = 0;
		break;

	case COSEM_TYPE_BOOLEAN:
		if (len < 2) return -ENODATA;
		result->value.u64 = data[1];
		consumed = 2;
		break;

	case COSEM_TYPE_UINT8:
	case COSEM_TYPE_ENUM:
		if (len < 2) return -ENODATA;
		result->value.u64 = data[1];
		consumed = 2;
		break;

	case COSEM_TYPE_INT8:
		if (len < 2) return -ENODATA;
		result->value.i64 = (int8_t)data[1];
		consumed = 2;
		break;

	case COSEM_TYPE_UINT16:
		if (len < 3) return -ENODATA;
		result->value.u64 = (data[1] << 8) | data[2];
		consumed = 3;
		break;

	case COSEM_TYPE_INT16:
		if (len < 3) return -ENODATA;
		result->value.i64 = (int16_t)((data[1] << 8) | data[2]);
		consumed = 3;
		break;

	case COSEM_TYPE_UINT32:
		if (len < 5) return -ENODATA;
		result->value.u64 = ((uint32_t)data[1] << 24) |
				    ((uint32_t)data[2] << 16) |
				    ((uint32_t)data[3] << 8) |
				    data[4];
		consumed = 5;
		break;

	case COSEM_TYPE_INT32:
		if (len < 5) return -ENODATA;
		result->value.i64 = (int32_t)(((uint32_t)data[1] << 24) |
					      ((uint32_t)data[2] << 16) |
					      ((uint32_t)data[3] << 8) |
					      data[4]);
		consumed = 5;
		break;

	case COSEM_TYPE_UINT64:
		if (len < 9) return -ENODATA;
		result->value.u64 = 0;
		for (int i = 0; i < 8; i++) {
			result->value.u64 = (result->value.u64 << 8) | data[1 + i];
		}
		consumed = 9;
		break;

	case COSEM_TYPE_INT64:
		if (len < 9) return -ENODATA;
		result->value.i64 = 0;
		for (int i = 0; i < 8; i++) {
			result->value.i64 = (result->value.i64 << 8) | data[1 + i];
		}
		consumed = 9;
		break;

	case COSEM_TYPE_FLOAT32: {
		if (len < 5) return -ENODATA;
		uint32_t fbits = ((uint32_t)data[1] << 24) |
				 ((uint32_t)data[2] << 16) |
				 ((uint32_t)data[3] << 8) |
				 data[4];
		float f;
		memcpy(&f, &fbits, sizeof(f));
		result->value.f64 = (double)f;
		result->data_type = COSEM_TYPE_FLOAT32;
		consumed = 5;
		break;
	}

	case COSEM_TYPE_FLOAT64: {
		if (len < 9) return -ENODATA;
		uint64_t dbits = 0;
		for (int i = 0; i < 8; i++) {
			dbits = (dbits << 8) | data[1 + i];
		}
		memcpy(&result->value.f64, &dbits, sizeof(double));
		consumed = 9;
		break;
	}

	case COSEM_TYPE_OCTET_STRING:
	case COSEM_TYPE_VISIBLE_STRING:
		if (len < 2) return -ENODATA;
		{
			uint8_t slen = data[1];
			if (len < (size_t)(2 + slen)) return -ENODATA;
			size_t copy_len = slen;
			if (copy_len > sizeof(result->value.raw.data)) {
				copy_len = sizeof(result->value.raw.data);
			}
			memcpy(result->value.raw.data, &data[2], copy_len);
			result->value.raw.len = copy_len;
			consumed = 2 + slen;
		}
		break;

	case COSEM_TYPE_STRUCTURE: {
		/* Structure: just record element count, caller handles elements */
		if (len < 2) return -ENODATA;
		result->value.u64 = data[1];  /* Element count */
		consumed = 2;
		break;
	}

	case COSEM_TYPE_ARRAY: {
		if (len < 2) return -ENODATA;
		result->value.u64 = data[1];  /* Element count */
		consumed = 2;
		break;
	}

	default:
		LOG_WRN("Unknown COSEM data type: 0x%02X", data[0]);
		return -ENOTSUP;
	}

	return (int)consumed;
}

int cosem_parse_get_response(const uint8_t *data, size_t len,
			     struct cosem_get_result *result)
{
	if (!data || !result || len < 4) {
		return -EINVAL;
	}

	memset(result, 0, sizeof(*result));

	/* Verify GET.response tag */
	if (data[0] != COSEM_TAG_GET_RESPONSE) {
		LOG_ERR("GET.response: Wrong tag: 0x%02X", data[0]);
		return -EPROTO;
	}

	uint8_t response_type = data[1];
	/* uint8_t invoke_id = data[2]; */

	if (response_type == GET_RESPONSE_NORMAL) {
		/*
		 * GET.response-normal:
		 *   C4 01 <invoke_id> <data-or-error>
		 *
		 * data: 00 <type> <value>  (Data choice)
		 * error: 01 <error-code>   (Data-Access-Result)
		 */
		if (len < 4) return -ENODATA;

		uint8_t choice = data[3];
		if (choice == 0x00) {
			/* Data present */
			int ret = cosem_decode_data(&data[4], len - 4, result);
			if (ret < 0) {
				return ret;
			}
			result->success = true;
			return 0;
		} else if (choice == 0x01) {
			/* Data-Access-Result error */
			uint8_t error = (len > 4) ? data[4] : 0xFF;
			LOG_ERR("GET.response: Data access error: %u", error);
			result->success = false;
			return -EACCES;
		}
	} else if (response_type == GET_RESPONSE_WITH_DATABLOCK) {
		LOG_WRN("GET.response with datablock — not yet supported");
		return -ENOTSUP;
	}

	return -EPROTO;
}

int cosem_build_rlrq(uint8_t *buf, size_t buf_size)
{
	if (!buf || buf_size < 3) {
		return -EINVAL;
	}

	/* RLRQ: 62 00 (Release Request, length 0 = normal release) */
	buf[0] = COSEM_TAG_RLRQ;
	buf[1] = 0x00;

	return 2;
}
```

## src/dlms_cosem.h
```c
/*
 * DLMS/COSEM Application Layer
 *
 * Implements COSEM AARQ (Association Request), GET.request PDU encoding,
 * and response decoding for reading OBIS code values from a DLMS meter.
 *
 * Supports Lowest Level Security (LLS) authentication.
 */

#ifndef DLMS_COSEM_H_
#define DLMS_COSEM_H_

#include <stdint.h>
#include <stddef.h>
#include <stdbool.h>

/* COSEM APDU tags */
#define COSEM_TAG_AARQ              0x60
#define COSEM_TAG_AARE              0x61
#define COSEM_TAG_GET_REQUEST       0xC0
#define COSEM_TAG_GET_RESPONSE      0xC4
#define COSEM_TAG_RLRQ              0x62  /* Release Request */
#define COSEM_TAG_RLRE              0x63  /* Release Response */

/* GET.request types */
#define GET_REQUEST_NORMAL          0x01
#define GET_REQUEST_NEXT            0x02
#define GET_REQUEST_WITH_LIST       0x03

/* GET.response types */
#define GET_RESPONSE_NORMAL         0x01
#define GET_RESPONSE_WITH_DATABLOCK 0x02
#define GET_RESPONSE_WITH_LIST      0x03

/* COSEM data types */
#define COSEM_TYPE_NULL_DATA        0x00
#define COSEM_TYPE_BOOLEAN          0x03
#define COSEM_TYPE_INT8             0x0F
#define COSEM_TYPE_UINT8            0x11
#define COSEM_TYPE_INT16            0x10
#define COSEM_TYPE_UINT16           0x12
#define COSEM_TYPE_INT32            0x05
#define COSEM_TYPE_UINT32           0x06
#define COSEM_TYPE_INT64            0x14
#define COSEM_TYPE_UINT64           0x15
#define COSEM_TYPE_FLOAT32          0x17
#define COSEM_TYPE_FLOAT64          0x18
#define COSEM_TYPE_OCTET_STRING     0x09
#define COSEM_TYPE_VISIBLE_STRING   0x0A
#define COSEM_TYPE_ENUM             0x16
#define COSEM_TYPE_STRUCTURE        0x02
#define COSEM_TYPE_ARRAY            0x01

/* OBIS code structure (6 bytes: A-B:C.D.E*F) */
struct obis_code {
	uint8_t a;
	uint8_t b;
	uint8_t c;
	uint8_t d;
	uint8_t e;
	uint8_t f;
};

/* COSEM attribute descriptor */
struct cosem_attr_desc {
	uint16_t         class_id;       /* Interface class (e.g. 3 = Register) */
	struct obis_code obis;           /* OBIS logical name */
	int8_t           attribute_id;   /* Attribute index (2 = value for Register) */
};

/* Parsed COSEM GET response */
struct cosem_get_result {
	bool   success;
	uint8_t data_type;       /* COSEM data type tag */
	union {
		int64_t   i64;
		uint64_t  u64;
		double    f64;
		float     f32;
		struct {
			uint8_t data[128];
			size_t  len;
		} raw;
	} value;
	/* For scaler-unit (Register class): scaler and unit */
	int8_t  scaler;          /* 10^scaler multiplier */
	uint8_t unit;            /* DLMS unit enum */
	bool    has_scaler_unit;
};

/**
 * @brief Build AARQ (Association Request) PDU
 *
 * Creates an AARQ for Logical Name referencing with optional
 * Lowest Level Security (LLS) password authentication.
 *
 * @param buf       Output buffer
 * @param buf_size  Size of output buffer
 * @param password  LLS password (NULL for no authentication)
 * @param pass_len  Password length
 * @return PDU length, or negative errno
 */
int cosem_build_aarq(uint8_t *buf, size_t buf_size,
		     const uint8_t *password, size_t pass_len);

/**
 * @brief Parse AARE (Association Response) PDU
 *
 * @param data  AARE PDU data
 * @param len   PDU length
 * @return 0 if association accepted, negative errno on failure/rejection
 */
int cosem_parse_aare(const uint8_t *data, size_t len);

/**
 * @brief Build GET.request-normal PDU
 *
 * @param buf       Output buffer
 * @param buf_size  Size of output buffer
 * @param invoke_id Invoke ID (caller tracks this)
 * @param attr      COSEM attribute descriptor (class + OBIS + attribute)
 * @return PDU length, or negative errno
 */
int cosem_build_get_request(uint8_t *buf, size_t buf_size,
			    uint8_t invoke_id,
			    const struct cosem_attr_desc *attr);

/**
 * @brief Parse GET.response PDU and extract value
 *
 * @param data    Response PDU data
 * @param len     PDU length
 * @param result  Output parsed result
 * @return 0 on success, negative errno on failure
 */
int cosem_parse_get_response(const uint8_t *data, size_t len,
			     struct cosem_get_result *result);

/**
 * @brief Build RLRQ (Release Request) PDU
 *
 * @param buf       Output buffer
 * @param buf_size  Size of output buffer
 * @return PDU length, or negative errno
 */
int cosem_build_rlrq(uint8_t *buf, size_t buf_size);

/**
 * @brief Decode a COSEM data value from raw bytes
 *
 * @param data   Raw data starting at the type tag
 * @param len    Available data length
 * @param result Output result with decoded value
 * @return Number of bytes consumed, or negative errno
 */
int cosem_decode_data(const uint8_t *data, size_t len,
		      struct cosem_get_result *result);

/**
 * @brief Convenience: create OBIS code from A-B:C.D.E*F notation
 */
static inline struct obis_code obis(uint8_t a, uint8_t b,
				    uint8_t c, uint8_t d,
				    uint8_t e, uint8_t f)
{
	return (struct obis_code){ a, b, c, d, e, f };
}

#endif /* DLMS_COSEM_H_ */
```

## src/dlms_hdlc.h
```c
/*
 * DLMS/COSEM HDLC Framing Layer — IEC 62056-46
 *
 * Implements HDLC frame encoding/decoding for DLMS over serial RS485.
 * Supports SNRM, UA, I-frame, DISC, and DM frame types.
 * Uses CRC-16/CCITT for HCS and FCS.
 */

#ifndef DLMS_HDLC_H_
#define DLMS_HDLC_H_

#include <stdint.h>
#include <stddef.h>
#include <stdbool.h>

/* HDLC constants */
#define HDLC_FLAG           0x7E
#define HDLC_FORMAT_TYPE    0xA0    /* Type 3 frame format */
#define HDLC_MAX_INFO_LEN   256
#define HDLC_MAX_FRAME_LEN  300

/* HDLC control byte values (U-frames) */
#define HDLC_CTRL_SNRM      0x93   /* Set Normal Response Mode */
#define HDLC_CTRL_UA         0x73   /* Unnumbered Acknowledge */
#define HDLC_CTRL_DISC       0x53   /* Disconnect */
#define HDLC_CTRL_DM         0x1F   /* Disconnected Mode */

/* I-frame control byte construction */
#define HDLC_CTRL_I_FRAME(send_seq, recv_seq, pf) \
	(((recv_seq) << 5) | ((pf) ? 0x10 : 0x00) | ((send_seq) << 1))

/* RR (Receive Ready) S-frame */
#define HDLC_CTRL_RR(recv_seq) \
	(0x01 | ((recv_seq) << 5))

/* HDLC address encoding */
#define HDLC_CLIENT_ADDR(logical_addr)  (uint8_t)(((logical_addr) << 1) | 1)
#define HDLC_SERVER_ADDR_1B(logical_addr) (uint8_t)(((logical_addr) << 1) | 1)

/* SNRM information field (negotiation parameters) */
struct hdlc_params {
	uint16_t max_info_tx;   /* Max info field length transmit */
	uint16_t max_info_rx;   /* Max info field length receive */
	uint8_t  window_tx;     /* Transmit window size */
	uint8_t  window_rx;     /* Receive window size */
};

/* Parsed HDLC frame */
struct hdlc_frame {
	uint8_t  dst_addr;
	uint8_t  src_addr;
	uint8_t  control;
	uint8_t  info[HDLC_MAX_INFO_LEN];
	uint16_t info_len;
	bool     segmented;     /* S-bit in format type */
	bool     valid;         /* CRC checks passed */
};

/**
 * @brief Calculate CRC-16/CCITT (HDLC FCS polynomial)
 *
 * @param data  Data to calculate CRC over
 * @param len   Length of data
 * @return CRC-16 value
 */
uint16_t hdlc_crc16(const uint8_t *data, size_t len);

/**
 * @brief Build an SNRM frame (connection setup)
 *
 * @param buf         Output buffer
 * @param buf_size    Size of output buffer
 * @param client_addr Client HDLC address
 * @param server_addr Server HDLC address (1-byte)
 * @param params      Optional negotiation params (NULL for defaults)
 * @return Frame length, or negative errno
 */
int hdlc_build_snrm(uint8_t *buf, size_t buf_size,
		     uint8_t client_addr, uint8_t server_addr,
		     const struct hdlc_params *params);

/**
 * @brief Build a DISC frame (disconnect)
 *
 * @param buf         Output buffer
 * @param buf_size    Size of output buffer
 * @param client_addr Client HDLC address
 * @param server_addr Server HDLC address
 * @return Frame length, or negative errno
 */
int hdlc_build_disc(uint8_t *buf, size_t buf_size,
		     uint8_t client_addr, uint8_t server_addr);

/**
 * @brief Build an I-frame containing COSEM APDU data
 *
 * @param buf         Output buffer
 * @param buf_size    Size of output buffer
 * @param client_addr Client HDLC address
 * @param server_addr Server HDLC address
 * @param send_seq    Send sequence number (0-7)
 * @param recv_seq    Receive sequence number (0-7)
 * @param info        Information field (COSEM APDU)
 * @param info_len    Length of information field
 * @return Frame length, or negative errno
 */
int hdlc_build_iframe(uint8_t *buf, size_t buf_size,
		      uint8_t client_addr, uint8_t server_addr,
		      uint8_t send_seq, uint8_t recv_seq,
		      const uint8_t *info, size_t info_len);

/**
 * @brief Parse a received HDLC frame
 *
 * @param data  Raw received data (should start/end with 0x7E)
 * @param len   Length of received data
 * @param frame Output parsed frame structure
 * @return 0 on success, negative errno on failure
 */
int hdlc_parse_frame(const uint8_t *data, size_t len, struct hdlc_frame *frame);

/**
 * @brief Extract HDLC frame from raw buffer (find 7E...7E boundaries)
 *
 * Scans for opening and closing 0x7E flags and returns the frame.
 *
 * @param data      Raw data buffer
 * @param len       Length of raw data
 * @param frame_start  Output: offset of frame start
 * @param frame_len    Output: length of complete frame
 * @return 0 if frame found, -EAGAIN if incomplete, -EINVAL if corrupt
 */
int hdlc_find_frame(const uint8_t *data, size_t len,
		    size_t *frame_start, size_t *frame_len);

#endif /* DLMS_HDLC_H_ */
```
